VERSION ""

NS_ :

BS_:

BU_: Host KincoDrive PowerStage LEDDriver

BO_ 257 KD_Bootloader_RX: 2 Host
 SG_ KD_Boot_Cmd : 0|8@1+ (1,0) [0|255] "" KincoDrive

BO_ 258 KD_Bootloader_TX: 8 KincoDrive
 SG_ KD_Boot_Resp : 0|8@1+ (1,0) [0|255] "" Host

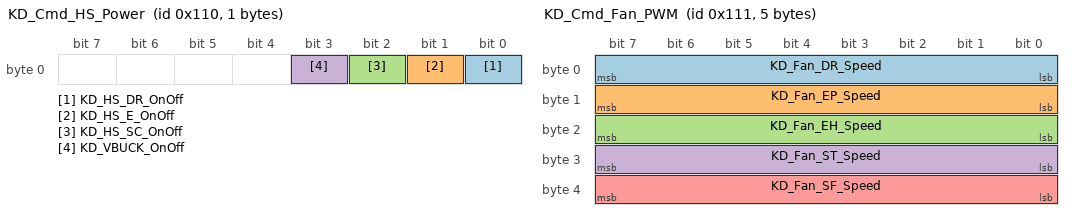
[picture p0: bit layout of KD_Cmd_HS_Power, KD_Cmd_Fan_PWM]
BO_ 272 KD_Cmd_HS_Power: 1 Host
 SG_ KD_HS_DR_OnOff : 0|1@1+ (1,0) [0|1] "" KincoDrive
 SG_ KD_HS_E_OnOff : 1|1@1+ (1,0) [0|1] "" KincoDrive
 SG_ KD_HS_SC_OnOff : 2|1@1+ (1,0) [0|1] "" KincoDrive
 SG_ KD_VBUCK_OnOff : 3|1@1+ (1,0) [0|1] "" KincoDrive

BO_ 273 KD_Cmd_Fan_PWM: 5 Host
 SG_ KD_Fan_DR_Speed : 0|8@1+ (1,0) [0|100] "%" KincoDrive
 SG_ KD_Fan_EP_Speed : 8|8@1+ (1,0) [0|100] "%" KincoDrive
 SG_ KD_Fan_EH_Speed : 16|8@1+ (1,0) [0|100] "%" KincoDrive
 SG_ KD_Fan_ST_Speed : 24|8@1+ (1,0) [0|100] "%" KincoDrive
 SG_ KD_Fan_SF_Speed : 32|8@1+ (1,0) [0|100] "%" KincoDrive

BO_ 274 KD_Cmd_EEPROM: 1 Host
 SG_ KD_EEPROM_Action : 0|8@1+ (1,0) [0|1] "" KincoDrive

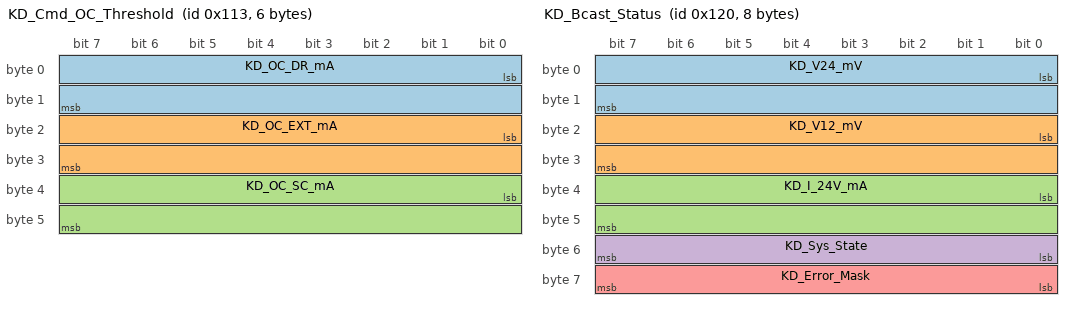
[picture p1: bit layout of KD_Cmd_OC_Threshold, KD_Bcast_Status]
BO_ 275 KD_Cmd_OC_Threshold: 6 Host
 SG_ KD_OC_DR_mA : 0|16@1+ (1,0) [0|65535] "mA" KincoDrive
 SG_ KD_OC_EXT_mA : 16|16@1+ (1,0) [0|65535] "mA" KincoDrive
 SG_ KD_OC_SC_mA : 32|16@1+ (1,0) [0|65535] "mA" KincoDrive

BO_ 276 KD_Cmd_UV_Threshold: 4 Host
 SG_ KD_UV_24V_mV : 0|16@1+ (1,0) [0|65535] "mV" KincoDrive
 SG_ KD_UV_12V_mV : 16|16@1+ (1,0) [0|65535] "mV" KincoDrive

BO_ 288 KD_Bcast_Status: 8 KincoDrive
 SG_ KD_V24_mV : 0|16@1+ (1,0) [0|65535] "mV" Host
 SG_ KD_V12_mV : 16|16@1+ (1,0) [0|65535] "mV" Host
 SG_ KD_I_24V_mA : 32|16@1+ (1,0) [0|65535] "mA" Host
 SG_ KD_Sys_State : 48|8@1+ (1,0) [0|2] "" Host
 SG_ KD_Error_Mask : 56|8@1+ (1,0) [0|255] "" Host

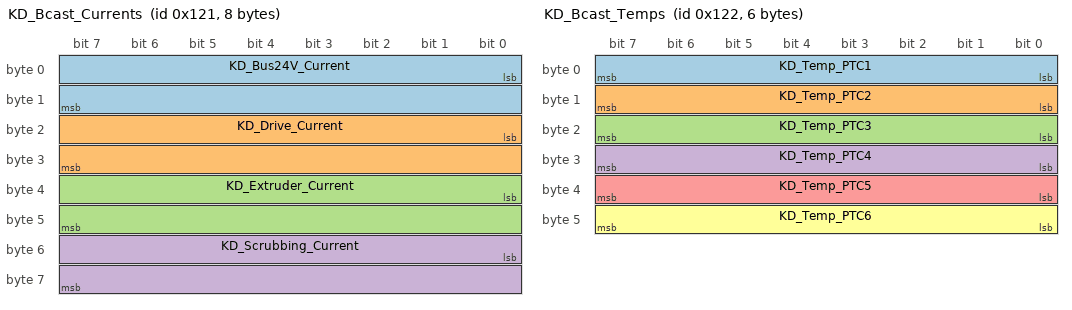
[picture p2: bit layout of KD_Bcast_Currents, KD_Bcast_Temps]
BO_ 289 KD_Bcast_Currents: 8 KincoDrive
 SG_ KD_Bus24V_Current : 0|16@1+ (1,0) [0|65535] "mA" Host
 SG_ KD_Drive_Current : 16|16@1+ (1,0) [0|65535] "mA" Host
 SG_ KD_Extruder_Current : 32|16@1+ (1,0) [0|65535] "mA" Host
 SG_ KD_Scrubbing_Current : 48|16@1+ (1,0) [0|65535] "mA" Host

BO_ 290 KD_Bcast_Temps: 6 KincoDrive
 SG_ KD_Temp_PTC1 : 0|8@1+ (1,-40) [-40|215] "degC" Host
 SG_ KD_Temp_PTC2 : 8|8@1+ (1,-40) [-40|215] "degC" Host
 SG_ KD_Temp_PTC3 : 16|8@1+ (1,-40) [-40|215] "degC" Host
 SG_ KD_Temp_PTC4 : 24|8@1+ (1,-40) [-40|215] "degC" Host
 SG_ KD_Temp_PTC5 : 32|8@1+ (1,-40) [-40|215] "degC" Host
 SG_ KD_Temp_PTC6 : 40|8@1+ (1,-40) [-40|215] "degC" Host

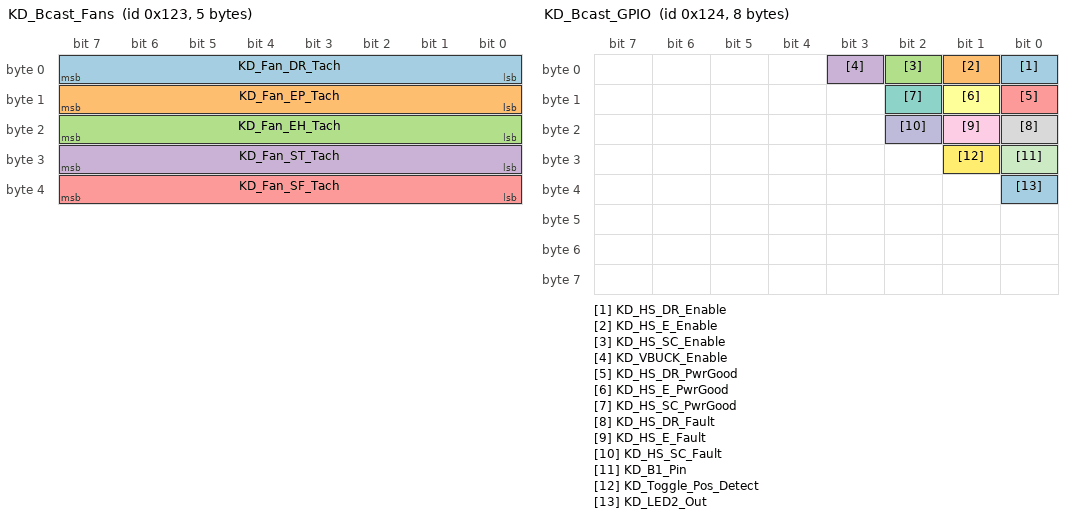
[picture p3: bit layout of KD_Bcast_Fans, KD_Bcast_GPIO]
BO_ 291 KD_Bcast_Fans: 5 KincoDrive
 SG_ KD_Fan_DR_Tach : 0|8@1+ (1,0) [0|100] "%" Host
 SG_ KD_Fan_EP_Tach : 8|8@1+ (1,0) [0|100] "%" Host
 SG_ KD_Fan_EH_Tach : 16|8@1+ (1,0) [0|100] "%" Host
 SG_ KD_Fan_ST_Tach : 24|8@1+ (1,0) [0|100] "%" Host
 SG_ KD_Fan_SF_Tach : 32|8@1+ (1,0) [0|100] "%" Host

BO_ 292 KD_Bcast_GPIO: 8 KincoDrive
 SG_ KD_HS_DR_Enable : 0|1@1+ (1,0) [0|1] "" Host
 SG_ KD_HS_E_Enable : 1|1@1+ (1,0) [0|1] "" Host
 SG_ KD_HS_SC_Enable : 2|1@1+ (1,0) [0|1] "" Host
 SG_ KD_VBUCK_Enable : 3|1@1+ (1,0) [0|1] "" Host
 SG_ KD_HS_DR_PwrGood : 8|1@1+ (1,0) [0|1] "" Host
 SG_ KD_HS_E_PwrGood : 9|1@1+ (1,0) [0|1] "" Host
 SG_ KD_HS_SC_PwrGood : 10|1@1+ (1,0) [0|1] "" Host
 SG_ KD_HS_DR_Fault : 16|1@1+ (1,0) [0|1] "" Host
 SG_ KD_HS_E_Fault : 17|1@1+ (1,0) [0|1] "" Host
 SG_ KD_HS_SC_Fault : 18|1@1+ (1,0) [0|1] "" Host
 SG_ KD_B1_Pin : 24|1@1+ (1,0) [0|1] "" Host
 SG_ KD_Toggle_Pos_Detect : 25|1@1+ (1,0) [0|1] "" Host
 SG_ KD_LED2_Out : 32|1@1+ (1,0) [0|1] "" Host

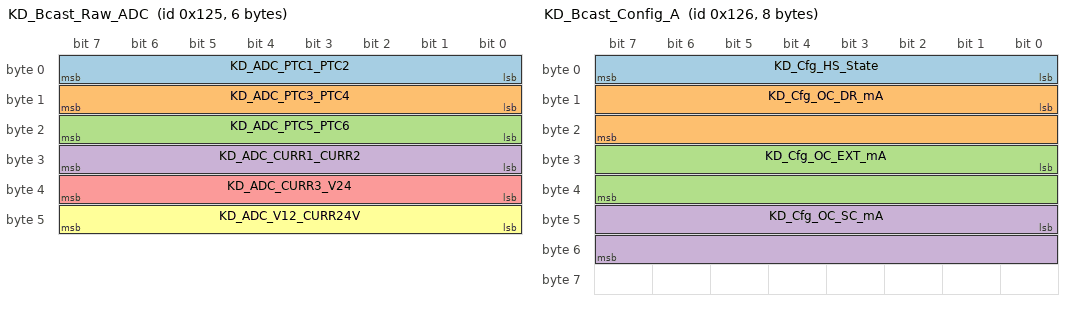
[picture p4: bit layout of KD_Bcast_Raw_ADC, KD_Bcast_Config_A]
BO_ 293 KD_Bcast_Raw_ADC: 6 KincoDrive
 SG_ KD_ADC_PTC1_PTC2 : 0|8@1+ (1,0) [0|255] "" Host
 SG_ KD_ADC_PTC3_PTC4 : 8|8@1+ (1,0) [0|255] "" Host
 SG_ KD_ADC_PTC5_PTC6 : 16|8@1+ (1,0) [0|255] "" Host
 SG_ KD_ADC_CURR1_CURR2 : 24|8@1+ (1,0) [0|255] "" Host
 SG_ KD_ADC_CURR3_V24 : 32|8@1+ (1,0) [0|255] "" Host
 SG_ KD_ADC_V12_CURR24V : 40|8@1+ (1,0) [0|255] "" Host

BO_ 294 KD_Bcast_Config_A: 8 KincoDrive
 SG_ KD_Cfg_HS_State : 0|8@1+ (1,0) [0|15] "" Host
 SG_ KD_Cfg_OC_DR_mA : 8|16@1+ (1,0) [0|65535] "mA" Host
 SG_ KD_Cfg_OC_EXT_mA : 24|16@1+ (1,0) [0|65535] "mA" Host
 SG_ KD_Cfg_OC_SC_mA : 40|16@1+ (1,0) [0|65535] "mA" Host

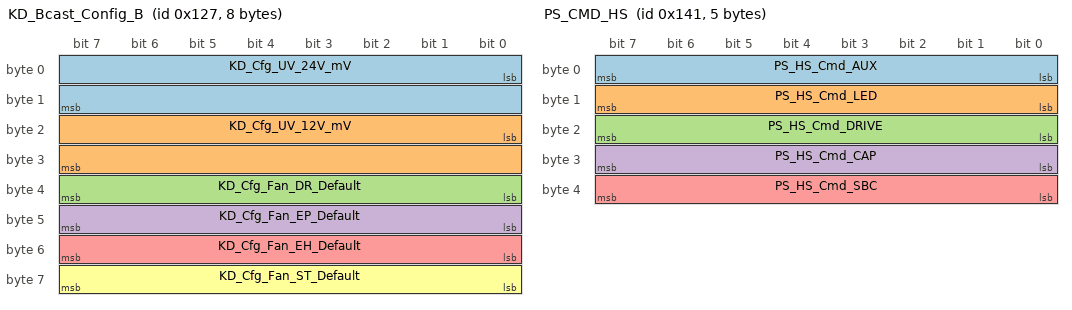
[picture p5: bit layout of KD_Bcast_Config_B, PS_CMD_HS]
BO_ 295 KD_Bcast_Config_B: 8 KincoDrive
 SG_ KD_Cfg_UV_24V_mV : 0|16@1+ (1,0) [0|65535] "mV" Host
 SG_ KD_Cfg_UV_12V_mV : 16|16@1+ (1,0) [0|65535] "mV" Host
 SG_ KD_Cfg_Fan_DR_Default : 32|8@1+ (1,0) [0|100] "%" Host
 SG_ KD_Cfg_Fan_EP_Default : 40|8@1+ (1,0) [0|100] "%" Host
 SG_ KD_Cfg_Fan_EH_Default : 48|8@1+ (1,0) [0|100] "%" Host
 SG_ KD_Cfg_Fan_ST_Default : 56|8@1+ (1,0) [0|100] "%" Host

BO_ 304 PS_DEVICE_ADDR: 2 Host
 SG_ PS_Device_Command : 0|8@1+ (1,0) [0|255] "" PowerStage

BO_ 305 PS_Bootloader_TX: 8 PowerStage
 SG_ PS_Boot_Resp : 0|8@1+ (1,0) [0|255] "" Host

BO_ 320 PS_CMD_FAN: 2 Host
 SG_ PS_Fan_Mode : 0|8@1+ (1,0) [0|2] "" PowerStage
 SG_ PS_Fan_Duty : 8|8@1+ (1,0) [0|100] "%" PowerStage

BO_ 321 PS_CMD_HS: 5 Host
 SG_ PS_HS_Cmd_AUX : 0|8@1+ (1,0) [0|1] "" PowerStage
 SG_ PS_HS_Cmd_LED : 8|8@1+ (1,0) [0|1] "" PowerStage
 SG_ PS_HS_Cmd_DRIVE : 16|8@1+ (1,0) [0|1] "" PowerStage
 SG_ PS_HS_Cmd_CAP : 24|8@1+ (1,0) [0|1] "" PowerStage
 SG_ PS_HS_Cmd_SBC : 32|8@1+ (1,0) [0|1] "" PowerStage

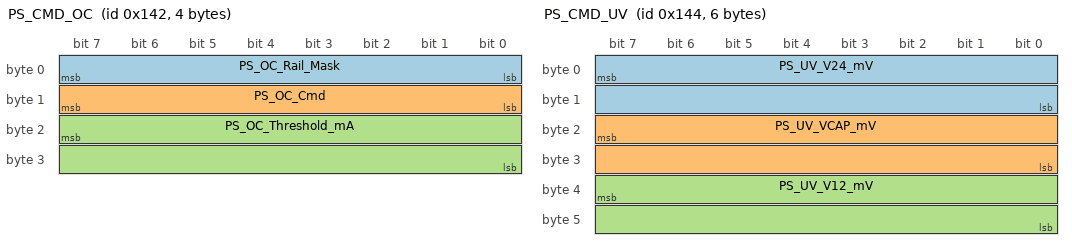
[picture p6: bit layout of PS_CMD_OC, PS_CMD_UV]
BO_ 322 PS_CMD_OC: 4 Host
 SG_ PS_OC_Rail_Mask : 0|8@1+ (1,0) [0|255] "" PowerStage
 SG_ PS_OC_Cmd : 8|8@1+ (1,0) [0|255] "" PowerStage
 SG_ PS_OC_Threshold_mA : 23|16@0+ (1,0) [0|50000] "mA" PowerStage

BO_ 323 PS_CMD_EEPROM: 1 Host
 SG_ PS_EEPROM_Cmd : 0|8@1+ (1,0) [0|255] "" PowerStage

BO_ 324 PS_CMD_UV: 6 Host
 SG_ PS_UV_V24_mV : 7|16@0+ (1,0) [0|30000] "mV" PowerStage
 SG_ PS_UV_VCAP_mV : 23|16@0+ (1,0) [0|30000] "mV" PowerStage
 SG_ PS_UV_V12_mV : 39|16@0+ (1,0) [0|15000] "mV" PowerStage

BO_ 325 PS_CMD_CTRL: 2 Host
 SG_ PS_V_LED_PWR_Cmd : 0|8@1+ (1,0) [0|1] "" PowerStage
 SG_ PS_CAN_Relay_Enable : 8|8@1+ (1,0) [0|1] "" PowerStage

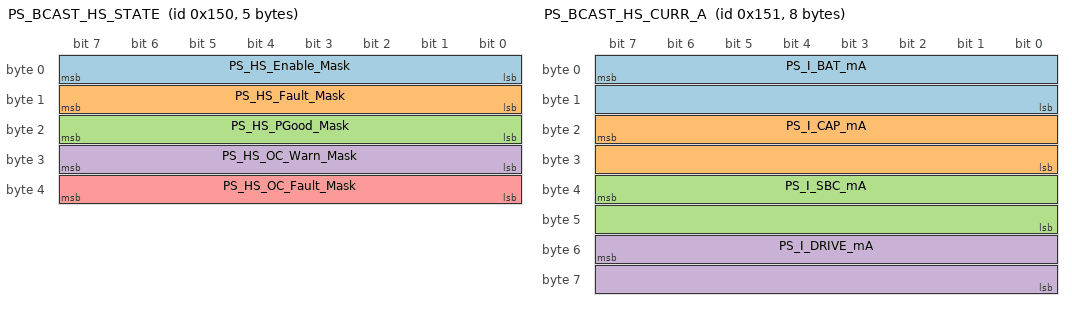
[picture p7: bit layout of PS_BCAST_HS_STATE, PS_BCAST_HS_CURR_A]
BO_ 336 PS_BCAST_HS_STATE: 5 PowerStage
 SG_ PS_HS_Enable_Mask : 0|8@1+ (1,0) [0|31] "" Host
 SG_ PS_HS_Fault_Mask : 8|8@1+ (1,0) [0|31] "" Host
 SG_ PS_HS_PGood_Mask : 16|8@1+ (1,0) [0|31] "" Host
 SG_ PS_HS_OC_Warn_Mask : 24|8@1+ (1,0) [0|31] "" Host
 SG_ PS_HS_OC_Fault_Mask : 32|8@1+ (1,0) [0|31] "" Host

BO_ 337 PS_BCAST_HS_CURR_A: 8 PowerStage
 SG_ PS_I_BAT_mA : 7|16@0+ (1,0) [0|50000] "mA" Host
 SG_ PS_I_CAP_mA : 23|16@0+ (1,0) [0|50000] "mA" Host
 SG_ PS_I_SBC_mA : 39|16@0+ (1,0) [0|50000] "mA" Host
 SG_ PS_I_DRIVE_mA : 55|16@0+ (1,0) [0|50000] "mA" Host

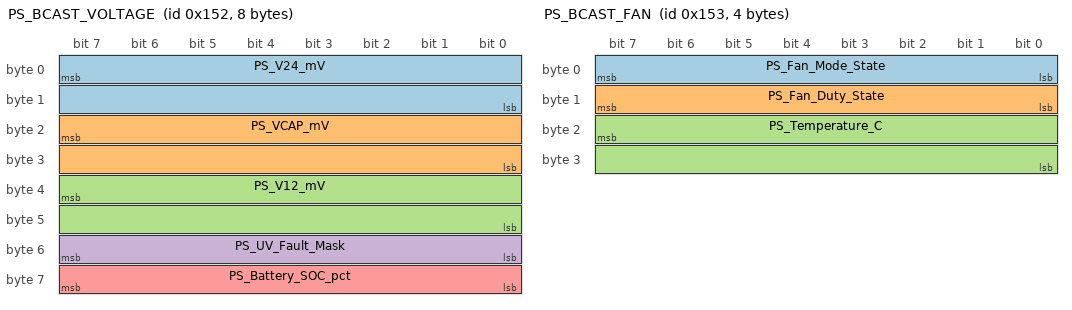
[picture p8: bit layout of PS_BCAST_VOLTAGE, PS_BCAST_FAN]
BO_ 338 PS_BCAST_VOLTAGE: 8 PowerStage
 SG_ PS_V24_mV : 7|16@0+ (1,0) [0|30000] "mV" Host
 SG_ PS_VCAP_mV : 23|16@0+ (1,0) [0|30000] "mV" Host
 SG_ PS_V12_mV : 39|16@0+ (1,0) [0|15000] "mV" Host
 SG_ PS_UV_Fault_Mask : 48|8@1+ (1,0) [0|7] "" Host
 SG_ PS_Battery_SOC_pct : 56|8@1+ (1,0) [0|100] "%" Host

BO_ 339 PS_BCAST_FAN: 4 PowerStage
 SG_ PS_Fan_Mode_State : 0|8@1+ (1,0) [0|2] "" Host
 SG_ PS_Fan_Duty_State : 8|8@1+ (1,0) [0|100] "%" Host
 SG_ PS_Temperature_C : 23|16@0- (0.1,0) [-40|150] "degC" Host

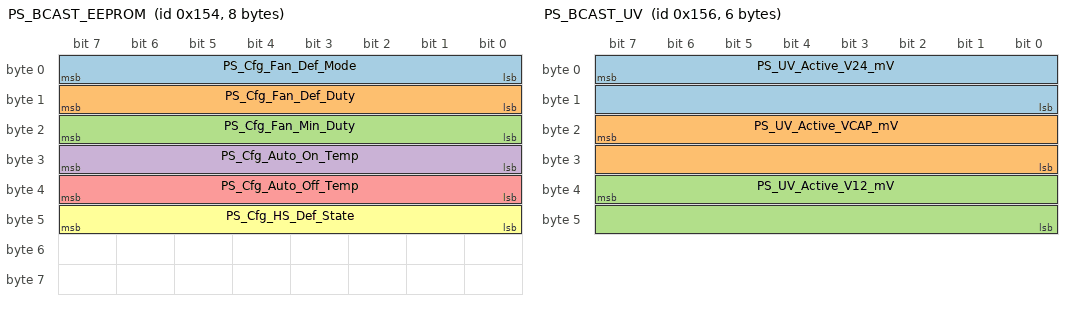
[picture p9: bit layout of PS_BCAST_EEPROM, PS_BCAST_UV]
BO_ 340 PS_BCAST_EEPROM: 8 PowerStage
 SG_ PS_Cfg_Fan_Def_Mode : 0|8@1+ (1,0) [0|2] "" Host
 SG_ PS_Cfg_Fan_Def_Duty : 8|8@1+ (1,0) [0|100] "%" Host
 SG_ PS_Cfg_Fan_Min_Duty : 16|8@1+ (1,0) [0|100] "%" Host
 SG_ PS_Cfg_Auto_On_Temp : 24|8@1+ (1,0) [0|150] "degC" Host
 SG_ PS_Cfg_Auto_Off_Temp : 32|8@1+ (1,0) [0|150] "degC" Host
 SG_ PS_Cfg_HS_Def_State : 40|8@1+ (1,0) [0|31] "" Host

BO_ 341 PS_BCAST_HS_CURR_B: 4 PowerStage
 SG_ PS_I_AUX_mA : 7|16@0+ (1,0) [0|50000] "mA" Host
 SG_ PS_I_LED_mA : 23|16@0+ (1,0) [0|50000] "mA" Host

BO_ 342 PS_BCAST_UV: 6 PowerStage
 SG_ PS_UV_Active_V24_mV : 7|16@0+ (1,0) [0|30000] "mV" Host
 SG_ PS_UV_Active_VCAP_mV : 23|16@0+ (1,0) [0|30000] "mV" Host
 SG_ PS_UV_Active_V12_mV : 39|16@0+ (1,0) [0|15000] "mV" Host

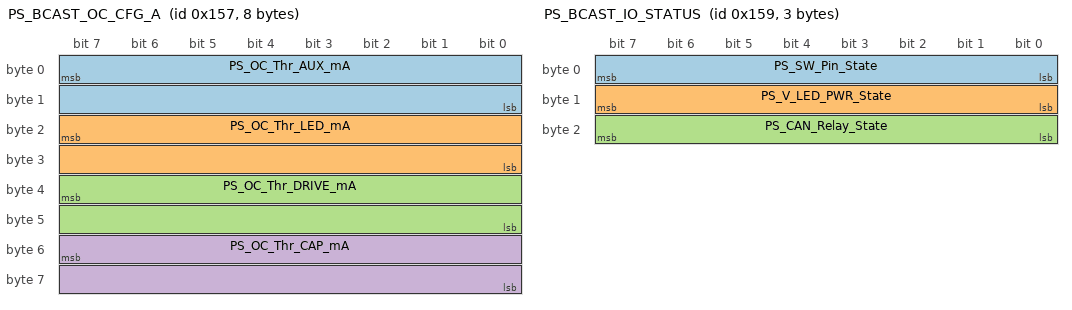
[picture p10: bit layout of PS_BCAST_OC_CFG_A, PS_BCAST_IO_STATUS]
BO_ 343 PS_BCAST_OC_CFG_A: 8 PowerStage
 SG_ PS_OC_Thr_AUX_mA : 7|16@0+ (1,0) [0|50000] "mA" Host
 SG_ PS_OC_Thr_LED_mA : 23|16@0+ (1,0) [0|50000] "mA" Host
 SG_ PS_OC_Thr_DRIVE_mA : 39|16@0+ (1,0) [0|50000] "mA" Host
 SG_ PS_OC_Thr_CAP_mA : 55|16@0+ (1,0) [0|50000] "mA" Host

BO_ 344 PS_BCAST_OC_CFG_B: 2 PowerStage
 SG_ PS_OC_Thr_SBC_mA : 7|16@0+ (1,0) [0|50000] "mA" Host

BO_ 345 PS_BCAST_IO_STATUS: 3 PowerStage
 SG_ PS_SW_Pin_State : 0|8@1+ (1,0) [0|1] "" Host
 SG_ PS_V_LED_PWR_State : 8|8@1+ (1,0) [0|1] "" Host
 SG_ PS_CAN_Relay_State : 16|8@1+ (1,0) [0|1] "" Host

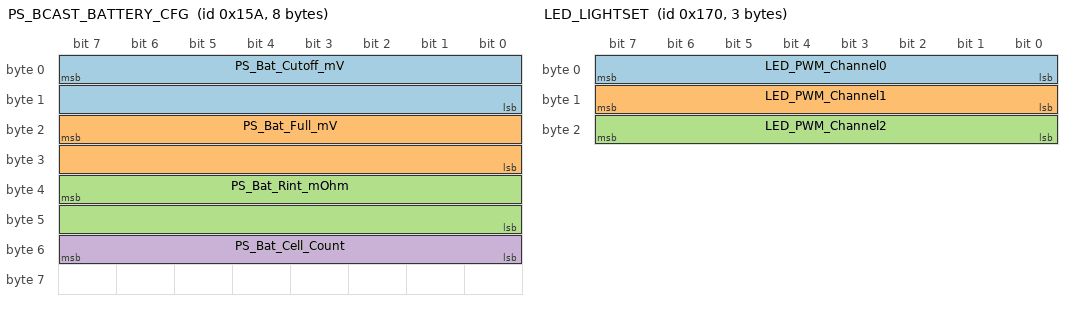
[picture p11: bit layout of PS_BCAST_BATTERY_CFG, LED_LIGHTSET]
BO_ 346 PS_BCAST_BATTERY_CFG: 8 PowerStage
 SG_ PS_Bat_Cutoff_mV : 7|16@0+ (1,0) [0|65535] "mV" Host
 SG_ PS_Bat_Full_mV : 23|16@0+ (1,0) [0|65535] "mV" Host
 SG_ PS_Bat_Rint_mOhm : 39|16@0+ (1,0) [0|65535] "mOhm" Host
 SG_ PS_Bat_Cell_Count : 48|8@1+ (1,0) [0|16] "" Host

BO_ 352 LED_DEVICEID: 2 Host
 SG_ LED_Boot_Cmd : 0|8@1+ (1,0) [0|255] "" LEDDriver

BO_ 353 LED_Bootloader_TX: 8 LEDDriver
 SG_ LED_Boot_Resp : 0|8@1+ (1,0) [0|255] "" Host

BO_ 368 LED_LIGHTSET: 3 Host
 SG_ LED_PWM_Channel0 : 0|8@1+ (1,0) [0|100] "%" LEDDriver
 SG_ LED_PWM_Channel1 : 8|8@1+ (1,0) [0|100] "%" LEDDriver
 SG_ LED_PWM_Channel2 : 16|8@1+ (1,0) [0|100] "%" LEDDriver

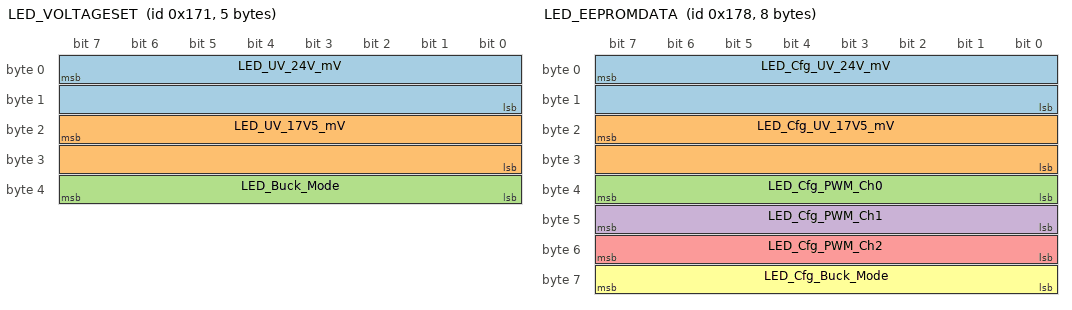
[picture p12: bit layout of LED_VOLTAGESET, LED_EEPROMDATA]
BO_ 369 LED_VOLTAGESET: 5 Host
 SG_ LED_UV_24V_mV : 7|16@0+ (1,0) [0|30000] "mV" LEDDriver
 SG_ LED_UV_17V5_mV : 23|16@0+ (1,0) [0|20000] "mV" LEDDriver
 SG_ LED_Buck_Mode : 32|8@1+ (1,0) [0|2] "" LEDDriver

BO_ 370 LED_EEPROMSET: 1 Host
 SG_ LED_EEPROM_Action : 0|8@1+ (1,0) [0|3] "" LEDDriver

BO_ 376 LED_EEPROMDATA: 8 LEDDriver
 SG_ LED_Cfg_UV_24V_mV : 7|16@0+ (1,0) [0|30000] "mV" Host
 SG_ LED_Cfg_UV_17V5_mV : 23|16@0+ (1,0) [0|20000] "mV" Host
 SG_ LED_Cfg_PWM_Ch0 : 32|8@1+ (1,0) [0|100] "%" Host
 SG_ LED_Cfg_PWM_Ch1 : 40|8@1+ (1,0) [0|100] "%" Host
 SG_ LED_Cfg_PWM_Ch2 : 48|8@1+ (1,0) [0|100] "%" Host
 SG_ LED_Cfg_Buck_Mode : 56|8@1+ (1,0) [0|2] "" Host

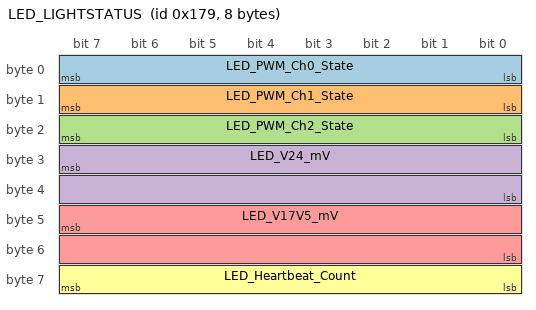
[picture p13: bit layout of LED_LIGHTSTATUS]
BO_ 377 LED_LIGHTSTATUS: 8 LEDDriver
 SG_ LED_PWM_Ch0_State : 0|8@1+ (1,0) [0|100] "%" Host
 SG_ LED_PWM_Ch1_State : 8|8@1+ (1,0) [0|100] "%" Host
 SG_ LED_PWM_Ch2_State : 16|8@1+ (1,0) [0|100] "%" Host
 SG_ LED_V24_mV : 31|16@0+ (1,0) [0|30000] "mV" Host
 SG_ LED_V17V5_mV : 47|16@0+ (1,0) [0|20000] "mV" Host
 SG_ LED_Heartbeat_Count : 56|8@1+ (1,0) [0|255] "" Host

BO_ 378 LED_DEVSTATUS: 2 LEDDriver
 SG_ LED_System_State : 0|8@1+ (1,0) [0|255] "" Host
 SG_ LED_Error_Code : 8|8@1+ (1,0) [0|255] "" Host

CM_ BU_ Host "Supervisory host or CAN analyzer. Issues commands to the three Fabrica devices and consumes their broadcasts.";
CM_ BU_ KincoDrive "Fabrica KincoDrive Control Module V5.4. Standard 11-bit IDs in 0x101-0x12F. Bootloader RX 0x101 / TX 0x102.";
CM_ BU_ PowerStage "Fabrica PowerStage Controller. Standard 11-bit IDs in 0x130-0x15F. Bootloader RX 0x130 / TX 0x131. Dual-bus relay (FDCAN1 internal, FDCAN2 host).";
CM_ BU_ LEDDriver "Fabrica 3-channel LED Driver. Standard 11-bit IDs in 0x160-0x17F. Bootloader RX 0x160 / TX 0x161.";

CM_ BO_ 257 "0x101 KincoDrive bootloader RX. byte0=0xFF DLC=2 = XCP CONNECT (also resets running app into bootloader).";
CM_ BO_ 258 "0x102 KincoDrive bootloader TX (XCP responses).";
CM_ BO_ 275 "0x113 KincoDrive: per-channel OC thresholds, uint16 LE × 3 (DR/EXT/SC) in mA.";
CM_ BO_ 276 "0x114 KincoDrive: undervoltage thresholds, uint16 LE × 2 (V24/V12) in mV.";
CM_ BO_ 295 "0x127 KincoDrive: BCAST_CONFIG_B - UV thresholds + fan boot defaults from EEPROM.";
CM_ SG_ 288 KD_Sys_State "0=INIT 1=LOAD_CONFIG 2=RUNNING";
CM_ SG_ 288 KD_Error_Mask "Bitmask: bit0=OC_DR bit1=OC_EXT bit2=OC_SC bit3=UV_24V bit4=UV_12V";
CM_ BO_ 304 "0x130 PowerStage DEVICE_ADDR / bootloader RX. byte0=0xFF DLC=2 resets into bootloader.";
CM_ BO_ 305 "0x131 PowerStage bootloader TX.";
CM_ BO_ 352 "0x160 LEDDriver DEVICEID / bootloader RX. byte0=0xFF DLC=2 resets into bootloader.";
CM_ BO_ 353 "0x161 LEDDriver bootloader TX.";

BA_DEF_  "BusType" STRING ;
BA_DEF_ BO_  "GenMsgCycleTime" INT 0 10000;
BA_DEF_ BO_  "GenMsgSendType"  STRING;
BA_DEF_DEF_  "BusType" "CAN";
BA_DEF_DEF_  "GenMsgCycleTime" 0;
BA_DEF_DEF_  "GenMsgSendType"  "Cyclic";

BA_ "GenMsgCycleTime" BO_ 288 500;
BA_ "GenMsgCycleTime" BO_ 289 500;
BA_ "GenMsgCycleTime" BO_ 290 500;
BA_ "GenMsgCycleTime" BO_ 291 500;
BA_ "GenMsgCycleTime" BO_ 292 500;
BA_ "GenMsgCycleTime" BO_ 293 500;
BA_ "GenMsgCycleTime" BO_ 294 500;
BA_ "GenMsgCycleTime" BO_ 295 500;
BA_ "GenMsgCycleTime" BO_ 336 500;
BA_ "GenMsgCycleTime" BO_ 337 500;
BA_ "GenMsgCycleTime" BO_ 338 500;
BA_ "GenMsgCycleTime" BO_ 339 500;
BA_ "GenMsgCycleTime" BO_ 340 500;
BA_ "GenMsgCycleTime" BO_ 341 500;
BA_ "GenMsgCycleTime" BO_ 342 500;
BA_ "GenMsgCycleTime" BO_ 343 500;
BA_ "GenMsgCycleTime" BO_ 344 500;
BA_ "GenMsgCycleTime" BO_ 345 500;
BA_ "GenMsgCycleTime" BO_ 346 500;
BA_ "GenMsgCycleTime" BO_ 376 1000;
BA_ "GenMsgCycleTime" BO_ 377 500;
BA_ "GenMsgCycleTime" BO_ 378 1000;

VAL_ 274 KD_EEPROM_Action 0 "LOAD_DEFAULTS_AND_APPLY" 1 "SAVE_CURRENT" ;
VAL_ 288 KD_Sys_State 0 "INIT" 1 "LOAD_CONFIG" 2 "RUNNING" ;
VAL_ 304 PS_Device_Command 255 "RESET_BOOTLOADER" ;
VAL_ 320 PS_Fan_Mode 0 "OFF" 1 "ON_MANUAL" 2 "AUTO" ;
VAL_ 321 PS_HS_Cmd_AUX 0 "DISABLE" 1 "ENABLE" ;
VAL_ 321 PS_HS_Cmd_LED 0 "DISABLE" 1 "ENABLE" ;
VAL_ 321 PS_HS_Cmd_DRIVE 0 "DISABLE" 1 "ENABLE" ;
VAL_ 321 PS_HS_Cmd_CAP 0 "DISABLE" 1 "ENABLE" ;
VAL_ 321 PS_HS_Cmd_SBC 0 "IGNORED" 1 "IGNORED" ;
VAL_ 322 PS_OC_Cmd 1 "SET_THRESHOLD" 2 "RESET_FAULT" ;
VAL_ 323 PS_EEPROM_Cmd 1 "SAVE_CONFIG" 2 "LOAD_DEFAULT" ;
VAL_ 325 PS_V_LED_PWR_Cmd 0 "OFF" 1 "ON" ;
VAL_ 325 PS_CAN_Relay_Enable 0 "DISABLE" 1 "ENABLE" ;
VAL_ 339 PS_Fan_Mode_State 0 "OFF" 1 "ON_MANUAL" 2 "AUTO" ;
VAL_ 340 PS_Cfg_Fan_Def_Mode 0 "OFF" 1 "ON_MANUAL" 2 "AUTO" ;
VAL_ 352 LED_Boot_Cmd 255 "RESET_BOOTLOADER" ;
VAL_ 369 LED_Buck_Mode 0 "MANUAL_OFF" 1 "MANUAL_ON" 2 "AUTO" ;
VAL_ 376 LED_Cfg_Buck_Mode 0 "MANUAL_OFF" 1 "MANUAL_ON" 2 "AUTO" ;
VAL_ 378 LED_System_State 0 "INIT" 1 "LOAD_CONFIG" 2 "RUNNING" 3 "ERROR" 4 "RECOVERY" ;
